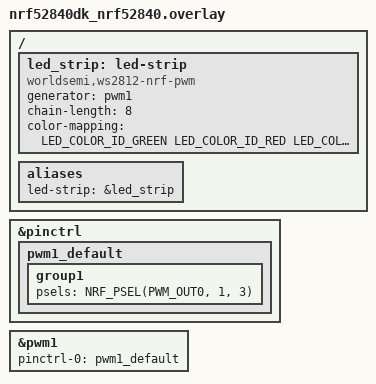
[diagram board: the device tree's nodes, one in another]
/*
 * Copyright (c) 2026 The Zephyr Project Contributors
 * Copyright (c) 2026 Dev It Wise
 *
 * SPDX-License-Identifier: Apache-2.0
 */

#include <zephyr/dt-bindings/led/led.h>

&pinctrl {
	pwm1_default: pwm1_default {
		group1 {
			psels = <NRF_PSEL(PWM_OUT0, 1, 3)>; /* Arduino D2 */
		};
	};
};

/*
 * pwm1 stays disabled on purpose: the strip below claims the instance, so
 * Zephyr's PWM driver must not bind it. Only its pinctrl state is needed,
 * because that is where the output pin selection lives.
 */
&pwm1 {
	pinctrl-0 = <&pwm1_default>;
	pinctrl-names = "default";
};

/ {
	led_strip: led-strip {
		compatible = "worldsemi,ws2812-nrf-pwm";
		status = "okay";
		generator = <&pwm1>;

		chain-length = <8>; /* arbitrary; change at will */
		color-mapping = <LED_COLOR_ID_GREEN
				 LED_COLOR_ID_RED
				 LED_COLOR_ID_BLUE>;
	};

	aliases {
		led-strip = &led_strip;
	};
};
